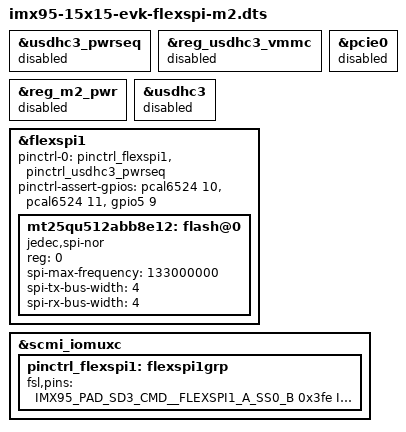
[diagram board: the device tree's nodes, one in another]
// SPDX-License-Identifier: (GPL-2.0+ OR MIT)
/*
 * Copyright 2024 NXP
 */

#include "imx95-15x15-evk.dts"

&usdhc3_pwrseq {
	status = "disabled";
};

&reg_usdhc3_vmmc {
	status = "disabled";
};

&reg_m2_pwr {
	status = "disabled";
};

&pcie0 {
	status = "disabled";
};

&usdhc3 {
	status = "disabled";
};

&flexspi1 {
	pinctrl-names = "default";
	pinctrl-0 = <&pinctrl_flexspi1>, <&pinctrl_usdhc3_pwrseq>;
	pinctrl-assert-gpios = <&pcal6524 10 GPIO_ACTIVE_HIGH>,	/* enable VCC_M2_3V3 */
			       <&pcal6524 11 GPIO_ACTIVE_HIGH>, /* enable SPI-NOR VCC 1.8v */
			       <&gpio5 9 GPIO_ACTIVE_HIGH>; /* put SPI-NOR RST pin to 1.8v */
	status = "okay";

	mt25qu512abb8e12: flash@0 {
		reg = <0>;
		#address-cells = <1>;
		#size-cells = <1>;
		compatible = "jedec,spi-nor";
		spi-max-frequency = <133000000>;
		spi-tx-bus-width = <4>;
		spi-rx-bus-width = <4>;
	};
};

&scmi_iomuxc {
	pinctrl_flexspi1: flexspi1grp {
		fsl,pins = <
			IMX95_PAD_SD3_CMD__FLEXSPI1_A_SS0_B		0x3fe
			IMX95_PAD_SD3_CLK__FLEXSPI1_A_SCLK		0x3fe
			IMX95_PAD_SD3_DATA0__FLEXSPI1_A_DATA_BIT0	0x3fe
			IMX95_PAD_SD3_DATA1__FLEXSPI1_A_DATA_BIT1	0x3fe
			IMX95_PAD_SD3_DATA2__FLEXSPI1_A_DATA_BIT2	0x3fe
			IMX95_PAD_SD3_DATA3__FLEXSPI1_A_DATA_BIT3	0x3fe
		>;
	};
};
